# LPC408x_7x register map
File version: 0.7
CPU: CM4 r0p0, little endian, no MPU, no FPU, 3 interrupt priority bits
Registers are 32-bit, read-write, reset 0x0 unless marked. A register's access mark holds for its fields unless they carry their own. Offsets are from the block's base; [hi:lo] are bit positions; {n}, {i} and the like mark numbered series.

## CANAFRAM — CAN acceptance filter RAM
Base 0x40038000
{0x0+4i} MASK[{i}] (i=0..511) reset not defined — CAN AF ram access register
  [31:0] MASK — CAN AF RAM mask

## CCAN — CAN controller
Base 0x40040000
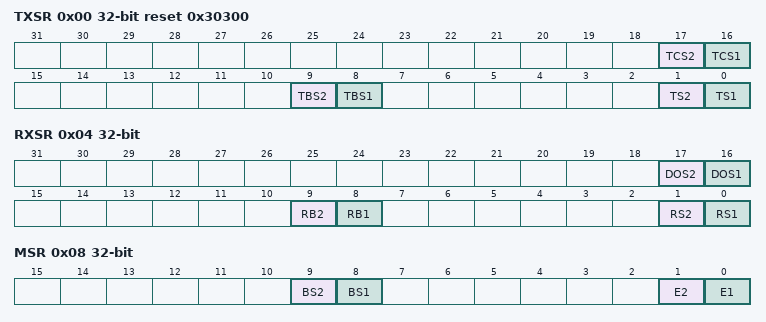
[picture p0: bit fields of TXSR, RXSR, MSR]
0x00 TXSR ro reset 0x30300 — CAN Central Transmit Status Register
  [17] TCS2 — When 1, all requested transmissions have been completed successfully by the CAN2 controller (same as TCS in CAN2GSR).
  [16] TCS1 — When 1, all requested transmissions have been completed successfully by the CAN1 controller (same as TCS in CAN1GSR).
  [9] TBS2 — When 1, all 3 Tx Buffers of the CAN2 controller are available to the CPU (same as TBS in CAN2GSR).
  [8] TBS1 — When 1, all 3 Tx Buffers of the CAN1 controller are available to the CPU (same as TBS in CAN1GSR).
  [1] TS2 — When 1, the CAN controller 2 is sending a message (same as TS in the CAN2GSR)
  [0] TS1 — When 1, the CAN controller 1 is sending a message (same as TS in the CAN1GSR).
0x04 RXSR ro — CAN Central Receive Status Register
  [17] DOS2 — When 1, a message was lost because the preceding message to CAN2 controller was not read out quickly enough (same as DOS in CAN2GSR).
  [16] DOS1 — When 1, a message was lost because the preceding message to CAN1 controller was not read out quickly enough (same as DOS in CAN1GSR).
  [9] RB2 — When 1, a received message is available in the CAN2 controller (same as RBS in CAN2GSR).
  [8] RB1 — When 1, a received message is available in the CAN1 controller (same as RBS in CAN1GSR).
  [1] RS2 — When 1, CAN2 is receiving a message (same as RS in CAN2GSR).
  [0] RS1 — When 1, CAN1 is receiving a message (same as RS in CAN1GSR).
0x08 MSR ro — CAN Central Miscellaneous Register
  [9] BS2 — When 1, the CAN2 controller is currently involved in bus activities (same as BS in CAN2GSR).
  [8] BS1 — When 1, the CAN1 controller is currently involved in bus activities (same as BS in CAN1GSR).
  [1] E2 — When 1, one or both of the CAN2 Tx and Rx Error Counters has reached the limit set in the CAN2EWL register (same as ES in CAN2GSR)
  [0] E1 — When 1, one or both of the CAN1 Tx and Rx Error Counters has reached the limit set in the CAN1EWL register (same as ES in CAN1GSR)

## DAC — Digital-to-Analog Converter (DAC) Modification
Base 0x4008C000
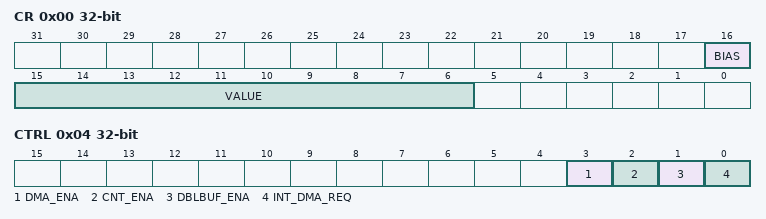
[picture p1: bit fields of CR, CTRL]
0x00 CR — D/A Converter Register. This register contains the digital value to be converted to analog and a power control bit.
  [16] BIAS — Settling time The settling times noted in the description of the BIAS bit are valid for a capacitance load on the DAC_OUT pin not exceeding 100 pF. A load impedance value greater than that value will cause settling time longer than the specified time. One or more graphs of load impedance vs. settling time will be included in the final data sheet.
    0=FAST (The settling time of the DAC is 1 us max, and the maximum current is 700 uA. This allows a maximum update rate of 1 MHz.); 1=SLOW (The settling time of the DAC is 2.5 us and the maximum current is 350 uA. This allows a maximum update rate of 400 kHz.)
  [15:6] VALUE — After the selected settling time after this field is written with a new VALUE, the voltage on the DAC_OUT pin (with respect to VSSA) is VALUE x ((VREFP - V REFN)/1024) + VREFN.
0x04 CTRL — DAC Control register. This register controls DMA and timer operation.
  [3] DMA_ENA — DMA access
    0=DISABLE; 1=ENABLE_DMA_BURST_RE (Enable. DMA Burst Request Input 7 is enabled for the DAC (see Table 672).)
  [2] CNT_ENA — Time-out counter operation
    0=DISABLE; 1=ENABLE
  [1] DBLBUF_ENA — Double buffering
    0=DISABLE; 1=ENABLE_WHEN_THIS_BI (Enable. When this bit and the CNT_ENA bit are both set, the double-buffering feature in the DACR register will be enabled. Writes to the DACR register are written to a pre-buffer and then transferred to the DACR on the next time-out of the counter.)
  [0] INT_DMA_REQ — DMA interrupt request
    0=CLEAR_ON_ANY_WRITE_T (Clear on any write to the DACR register.); 1=SET_BY_HARDWARE_WHEN (Set by hardware when the timer times out.)
0x08 CNTVAL — DAC Counter Value register. This register contains the reload value for the DAC DMA/Interrupt timer.
  [15:0] VALUE — 16-bit reload value for the DAC interrupt/DMA timer.
